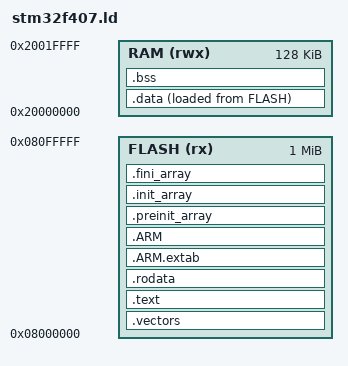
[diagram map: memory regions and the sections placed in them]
/**
 *	flightpanel - A Cortex-M4 based USB flight panel for flight simulators.
 *	Copyright (C) 2017-2017 Johannes Bauer
 *
 *	This file is part of flightpanel.
 *
 *	flightpanel is free software; you can redistribute it and/or modify
 *	it under the terms of the GNU General Public License as published by
 *	the Free Software Foundation; this program is ONLY licensed under
 *	version 3 of the License, later versions are explicitly excluded.
 *
 *	flightpanel is distributed in the hope that it will be useful,
 *	but WITHOUT ANY WARRANTY; without even the implied warranty of
 *	MERCHANTABILITY or FITNESS FOR A PARTICULAR PURPOSE.  See the
 *	GNU General Public License for more details.
 *
 *	You should have received a copy of the GNU General Public License
 *	along with flightpanel; if not, write to the Free Software
 *	Foundation, Inc., 59 Temple Place, Suite 330, Boston, MA  02111-1307  USA
 *
 *	Johannes Bauer <JohannesBauer@gmx.de>
**/

ENTRY(Reset_Handler)

MEMORY {
	FLASH(rx)	: ORIGIN = 0x8000000, LENGTH = 1024K
	RAM(rwx)	: ORIGIN = 0x20000000, LENGTH = 128K
}

_sflash = ORIGIN(FLASH);
_sram = ORIGIN(RAM);
_eram = ORIGIN(RAM) + LENGTH(RAM);

SECTIONS {
	.vectors : {
		. = ALIGN(4);
		KEEP(*(.vectors))
		. = ALIGN(4);
	} >FLASH

	.text : {
		. = ALIGN(4);
		*(.text)
		*(.text*)
		*(.glue_7)
		*(.glue_7t)
		*(.eh_frame)
		KEEP(*(.init))
		KEEP(*(.fini))
		. = ALIGN(4);
		_etext = .;
	} >FLASH

	.rodata : {
		. = ALIGN(4);
		*(.rodata)
		*(.rodata*)
		*(.jcr)
		. = ALIGN(4);
	} >FLASH

	.ARM.extab : {
		*(.ARM.extab* .gnu.linkonce.armextab.*)
	} >FLASH

	.ARM : {
		__exidx_start = .;
		*(.ARM.exidx*)
		__exidx_end = .;
	} >FLASH

	.preinit_array : {
		PROVIDE_HIDDEN(__preinit_array_start = .);
		KEEP(*(.preinit_array*))
		PROVIDE_HIDDEN(__preinit_array_end = .);
	} >FLASH

	.init_array : {
		PROVIDE_HIDDEN(__init_array_start = .);
		KEEP(*(SORT(.init_array.*)))
		KEEP(*(.init_array*))
		PROVIDE_HIDDEN(__init_array_end = .);
	} >FLASH

	.fini_array : {
		PROVIDE_HIDDEN(__fini_array_start = .);
		KEEP(*(SORT(.fini_array.*)))
		KEEP(*(.fini_array*))
		PROVIDE_HIDDEN(__fini_array_end = .);
	} >FLASH

	.data : {
		. = ALIGN(4);
		_sdata = .;
		*(.data)
		*(.data*)
		. = ALIGN(4);
		_edata = .;
	} >RAM AT> FLASH
	_sidata = LOADADDR(.data);

	.bss : {
		. = ALIGN(4);
		_sbss = .;
		__bss_start__ = _sbss;
		*(.bss)
		*(.bss*)
		*(COMMON)
		. = ALIGN(4);
		_ebss = .;
		__bss_end__ = _ebss;
	} >RAM
}
